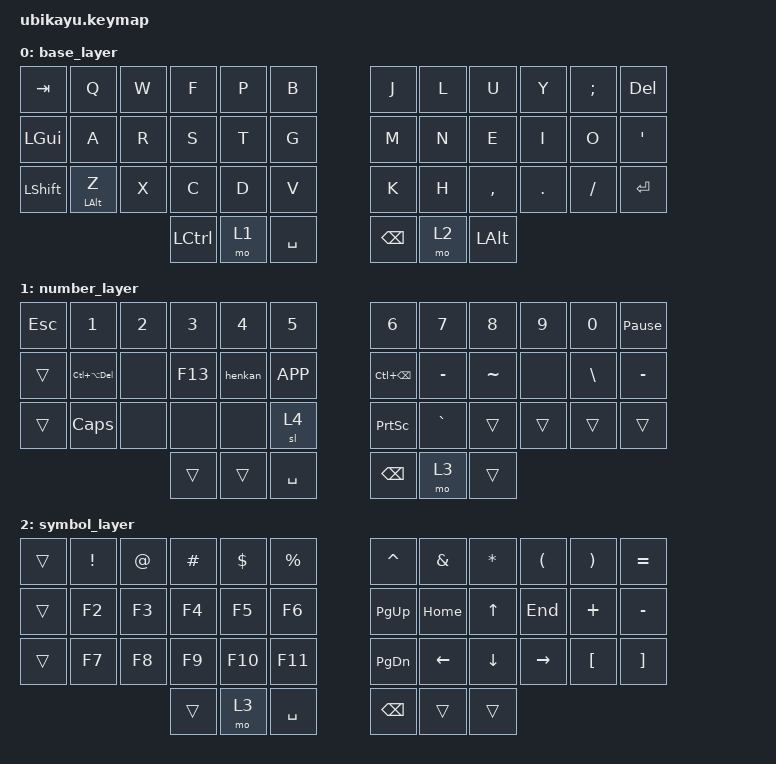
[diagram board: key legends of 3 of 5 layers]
/*
 * Copyright (c) 2020 The ZMK Contributors
 *
 * SPDX-License-Identifier: MIT
 */

#include <behaviors.dtsi>
#include <dt-bindings/led/led.h> /* bodo you need this to turn on ARGEEBEEH nowadays weh */
#include <dt-bindings/zmk/rgb.h>
#include <dt-bindings/zmk/keys.h>
#include <dt-bindings/zmk/bt.h>
// #include <dt-bindings/zmk/mouse.h>
#include "mouse.dtsi"

#define DEFAULT 0-base
#define LOWER   1-numbers
#define RAISE   2-symbols
#define ADJUST  3-misc-rgb-bt
#define GAMING  4-extra

/* &led_strip {
    chain-length = <16>;
}; */

&pinctrl {
    spi3_default: spi3_default {
        group1 {
            psels = <NRF_PSEL(SPIM_MOSI, 0, 6)>;
        };
    };

    spi3_sleep: spi3_sleep {
        group1 {
            psels = <NRF_PSEL(SPIM_MOSI, 0, 6)>;
            low-power-enable;
        };
    };
};

&spi3 {
    compatible = "nordic,nrf-spim";
    status = "okay";

    pinctrl-0 = <&spi3_default>;
    pinctrl-1 = <&spi3_sleep>;
    pinctrl-names = "default", "sleep";

    led_strip: ws2812@0 {
        compatible = "worldsemi,ws2812-spi";

        /* SPI */
        reg = <0>; /* ignored, but necessary for SPI bindings */
        spi-max-frequency = <4000000>;

        /* WS2812 */
        chain-length = <23>; /* number of LEDs */
        spi-one-frame = <0x70>;
        spi-zero-frame = <0x40>;
        color-mapping = <LED_COLOR_ID_GREEN
                            LED_COLOR_ID_RED
                            LED_COLOR_ID_BLUE>;

        };
};




/ {
    macros {
        henkan: henkan {
            compatible = "zmk,behavior-macro";
            #binding-cells = <0>;
            wait-ms = <40>;
            tap-ms = <40>;
            bindings
                = <&macro_press   &kp LALT>
                , <&macro_tap     &kp GRAVE>
                , <&macro_release &kp LALT>
                ;
        };
    };
        combos {
            compatible = "zmk,combos";
            timeout-ms = <100>;
            require-prior-idle-ms = <150>;

            combo_reset {
                key-positions = <14 15 16 25>;
                bindings = <&bootloader>;
            };
        };
};




/ {
        keymap {
                compatible = "zmk,keymap";

                base_layer {
// -------------------------------------------------------------------------------------
// |  TAB |  Q  |  W  |  E  |  R  |  T  |   |  Y  |  U   |  I  |  O  |  P  |   BKSP    |
// | CTRL |  A  |  S  |  D  |  F  |  G  |   |  H  |  J   |  K  |  L  |  ;  |    '      |
// | SHFT |  Z  |  X  |  C  |  V  |  B  |   |  N  |  M   |  ,  |  .  |  /  | SHFT(RET) |
//                         | ALT | LWR | SPC | RSE  | ALT |
//   &kp TAB   &kp Q &kp W &kp E &kp R &kp T   &kp Y &kp U  &kp I     &kp O   &kp P    &kp BSPC
//   &kp LCTRL &kp A &kp S &kp D &kp F &kp G   &kp H &kp J  &kp K     &kp L   &kp SEMI &kp SQT
//   &kp LSHFT &kp Z &kp X &kp C &kp V &kp B   &kp N &kp M  &kp COMMA &kp DOT &kp FSLH &mt RSHFT RET
//                        &kp LALT  &mo 1 &kp SPACE &mo 2  &kp RALT

                        bindings = <
&kp TAB     &kp Q   &kp W   &kp F   &kp P   &kp B          &kp J   &kp L   &kp U   &kp Y  &kp SEMI  &kp DEL
//&rgb_ug RGB_TOG     &kp Q   &kp W   &kp F   &kp P   &kp B          &rgb_ug RGB_EFF   &kp L   &kp U   &kp Y  &kp SEMI  &kp DEL
&kp LGUI &kp A  &kp R  &kp S    &kp T    &kp G            &kp M  &kp N    &kp E     &kp I   &kp O &kp SQT
&kp LSHFT &mt LALT Z  &kp X  &kp C    &kp D    &kp V       &kp K  &kp H    &kp COMMA &kp DOT &kp FSLH &kp ENTER
                        &kp LCTRL &mo 1  &kp SPACE &kp BSPC &mo 2  &kp LALT

                        >;
                };

                number_layer {
// ----------------------------------------------------------------------------------
// |    |  !  |  @  |  #  |  $  |  %  |   |  ^  |  &  |  *  |  (  |  )  |    DEL    |
// |    |  _  |  +  |  {  |  }  | "|" |   | LFT | DWN |  UP | RGT |  `  |     ~     |
// |    | ESC | GUI | ALT | CAPS|  "  |   | HOME| END | PGUP| PGDN| PRSC| SHFT(RET) |
//                       |     |     | RET | ADJ |     |
//   &trans &kp EXCL  &kp AT      &kp HASH &kp DLLR &kp PRCNT      &kp CARET &kp AMPS &kp N8    &kp LPAR  &kp RPAR  &kp DEL
//   &trans &kp MINUS &kp KP_PLUS &kp LBRC &kp RBRC &kp PIPE       &kp LEFT  &kp DOWN &kp UP    &kp RIGHT &kp GRAVE &kp TILDE
//   &trans &kp ESC   &kp LGUI    &kp LALT &kp CLCK &kp DQT        &kp HOME  &kp END  &kp PG_UP &kp PG_DN &kp PSCRN &mt RSHFT RET
//                                 &trans      &trans       &kp RET        &mo 3       &trans

                        bindings = <

&kp ESC &kp N1  &kp N2  &kp N3  &kp N4  &kp N5                        &kp N6  &kp N7  &kp N8  &kp N9  &kp N0  &kp PAUSE_BREAK
&trans  &kp LC(LA(DEL))   &none &kp F13 &henkan &kp K_APP      &kp LC(BSPC)    &kp MINUS   &kp TILDE   &none  &kp BSLH    &kp MINUS
&trans  &kp CAPS &none &none  &none  &sl 4 	                          &kp PSCRN &kp GRAVE &trans &trans &trans &trans
                        &trans &trans     &kp SPACE &kp BSPC    &mo 3 &trans
                        >;
                };

                symbol_layer {
// -----------------------------------------------------------------------------------------
// |    |  1  |  2  |  3  |  4  |  5  |   |  6  |  7  |  8  |  9  |  0  | DEL |
// |    |  -  |  =  |  [  |  ]  |  \  |   | F1  | F2  | F3  | F4  | F5  | F6  |
// |    | ESC | GUI | ALT | CAPS|  "  |   | F7  | F8  | F9  | F10 | F11 | F12 |
//                       |     | ADJ | BKSP |    |     |
//   &trans &kp N1    &kp N2    &kp N3    &kp N4    &kp N5        &kp N6    &kp N7    &kp N8    &kp N9    &kp N0    &kp DEL
//   &trans &kp MINUS &kp EQUAL &kp LBKT  &kp RBKT  &kp BSLH      &kp F1    &kp F2    &kp F3    &kp F4    &kp F5    &kp F6
//   &trans &kp ESC   &kp LGUI  &kp RALT  &kp CLCK  &kp DQT       &kp F7    &kp F8    &kp F9    &kp F10   &kp F11   &kp F12
//                                &trans      &mo 3       &kp BSPC        &trans      &trans
                        bindings = <
&trans     &kp EXCL &kp AT &kp POUND &kp DLLR  &kp PRCNT    &kp CARET  &kp AMPS    &kp ASTRK    &kp LPAR   &kp RPAR   &kp EQUAL
&trans   &kp F2 &kp F3 &kp F4  &kp F5  &kp F6               &kp PG_UP  &kp HOME  &kp UP &kp END   &kp PLUS &kp MINUS
&trans   &kp F7 &kp F8 &kp F9 &kp F10 &kp F11               &kp PG_DN &kp LEFT &kp DOWN &kp RIGHT &kp LBKT  &kp RBKT
                        &trans &mo 3  &kp SPACE &kp BSPC &trans  &trans
                        >;
                };

                mouse_layer {
// -----------------------------------------------------------------------------------------
// | RGB BRI+ | RGB SAT+ | RGB HUE+ | RGB ANI+ |    | RGB TOG |   |  BT1  |  | MU | BT4 | BT5 | BT CLR |
// | RGB BRI- | RGB SAT- | RGB HUE- | RGB ANI- |    |         |   |       | ML    | MD    | MR    |     |        |
// |          |          |          |          |    |         |   | RESET |     |     |     |     |        |
//                                              |     |     |     |     |     |
//   &rgb_ug RGB_BRI &rgb_ug RGB_SAI &rgb_ug RGB_HUI &rgb_ug RGB_EFF &none &rgb_ug RGB_TOG    &bt BT_SEL 0 &none &mmv MOVE_UP &bt BT_SEL 3 &bt BT_SEL 4 &bt BT_CLR
//   &rgb_ug RGB_BRD &rgb_ug RGB_SAD &rgb_ug RGB_HUD &rgb_ug RGB_EFR &none &none              &none        &none        &none        &none        &none        &none
//   &none           &none           &none           &none           &none &none              &reset       &none        &none        &none        &none        &none
//                                                             &trans      &trans       &tog 3        &trans      &trans
// mouse keys here: https://github.com/ftc/zmk/blob/mouse-ftc/docs/docs/behaviors/mouse-emulation.md
                        bindings = <
&none            &none           &none           &kp LC(LS(ESC))  &none  &none   	        &none  &mkp MB1         &mmv MOVE_UP    &mkp MB2        &none  &bt BT_CLR
&rgb_ug RGB_TOG  &rgb_ug RGB_HUI &rgb_ug RGB_BRI &rgb_ug RGB_SPI  &rgb_ug RGB_SAI  &kp C_VOL_UP       &none  &mmv MOVE_LEFT   &mmv MOVE_DOWN  &mmv MOVE_RIGHT &none  &none
&rgb_ug RGB_EFF  &rgb_ug RGB_HUD &rgb_ug RGB_BRD &rgb_ug RGB_SPD  &rgb_ug RGB_SAD  &kp C_VOL_DN       &none  &bt BT_SEL 0     &bt BT_SEL 1      &bt BT_SEL 2  &bt BT_SEL 3 &bt BT_SEL 4
                        &trans &trans &none  &trans  &trans
                        >;
                };

                extra_layer {
// -----------------------------------------------------------------------------------------
// | RGB BRI+ | RGB SAT+ | RGB HUE+ | RGB ANI+ |    | RGB TOG |   |  BT1  | BT2 | BT3 | BT4 | BT5 | BT CLR |
// | RGB BRI- | RGB SAT- | RGB HUE- | RGB ANI- |    |         |   |       |     |     |     |     |        |
// |          |          |          |          |    |         |   | RESET |     |     |     |     |        |
//                                              |     |     |     |     |     |
//   &rgb_ug RGB_BRI &rgb_ug RGB_SAI &rgb_ug RGB_HUI &rgb_ug RGB_EFF &none &rgb_ug RGB_TOG    &bt BT_SEL 0 &bt BT_SEL 1 &bt BT_SEL 2 &bt BT_SEL 3 &bt BT_SEL 4 &bt BT_CLR
//   &rgb_ug RGB_BRD &rgb_ug RGB_SAD &rgb_ug RGB_HUD &rgb_ug RGB_EFR &none &none              &none        &none        &none        &none        &none        &none
//   &none           &none           &none           &none           &none &none              &reset       &none        &none        &none        &none        &none
//                                                             &trans      &trans       &tog 3        &trans      &trans

                        bindings = <
&kp ESC &kp Q   &kp W   &kp E   &none   &tog 0    &none  &none   &kp Q  &kp W  &kp E  &none
&none   &kp A   &kp S   &kp D   &none   &kp F12    &none  &none   &kp A  &kp S  &kp D  &none
&none   &none   &none   &none   &none   &kp F5     &none  &none   &none  &none  &none  &none
                        &none  &none   &kp SPACE  &none   &none
                        >;
                };

        };
};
